# RN831X_RN861X_MCU register map
File version: v0.0.1
CPU: RN831X_RN861X_MCU r1p0, little endian, MPU, no FPU
Registers are 32-bit, read-write, reset 0x0 unless marked. A register's access mark holds for its fields unless they carry their own. Offsets are from the block's base; [hi:lo] are bit positions; {n}, {i} and the like mark numbered series; 'fields as' and 'values as' point back to an identical list.

## RTC_CORE0 — real time clock
Base 0x200B4000
Same registers: RTC_CORE1 0xA00B4000
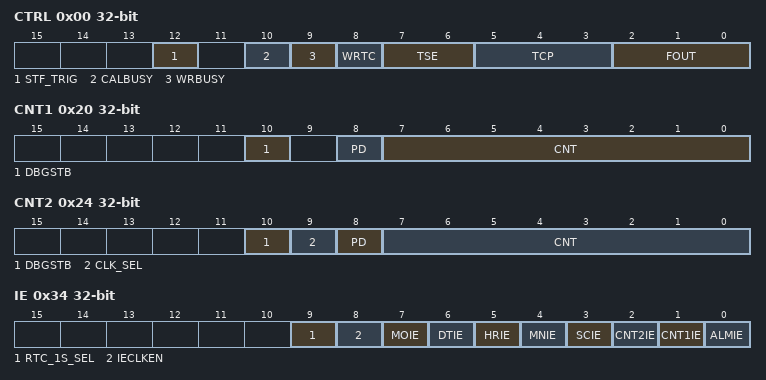
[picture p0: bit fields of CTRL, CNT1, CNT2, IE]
0x00 CTRL access per field — control register
  [12] STF_TRIG wo — software time freeze trigger bit(freezed timestamp will be save to 0x120~0x12C)
  [10] CALBUSY ro — RTC calibration busy flag
  [9] WRBUSY ro — RTC register writing busy flag (RTC register only can be changed or set when Wr_busy is 0)
  [8] WRTC rw — RTC register write enable/disable bit(controls offset 0x00-0x1C/0x3C/0xC4/0x168, except this field.)
    0=DIS (RTC register set as read_only); 1=EN (RTC register set as writable)
  [7:6] TSE rw — temparature compentation mode selection config bits.
    0=DIS (disable automatic temperature compensation); 1=AUTOEN (enable automatic cyclic temperature compensation); 2=USER0EN (enable user mode 0, automatic temperature compensation triggered by setting temperature(temperature set by user)); 3=USER1EN (enable user mode 1, automatic temperature compensation triggered by setting temperature(temperature unchangeable))
  [5:3] TCP rw — temperature compensation period bits
    0=2S (select temperature compensation period as 2 second(or 0.5s for 8025T)); 1=10S (select temperature compensation period as 10 second(or 2s for 8025T)); 2=20S (select temperature compensation period as 20 second(or 10s for 8025T)); 3=30S (select temperature compensation period as 30 second(or 30s for 8025T)); 4=1MIN (select temperature compensation period as 1 minute(not for 8025T)); 5=2MIN (select temperature compensation period as 2 minute(not for 8025T)); 6=5MIN (select temperature compensation period as 5 minute(not for 8025T)); 7=10MIN (select temperature compensation period as 10 minute(not for 8025T))
  [2:0] FOUT rw — RTC output frequency selections FOUT bits.
    0=NUL (RTCOUT forbidden); 1=PLLOUT (select RTCOUT as PLL, freq depend on PLLOUT_SEL); 2=1_30HZ (select RTCOUT as LOSC, frequency of 1/30Hz); 3=32KHZ (select RTCOUT as LOSC, frequency of 32768Hz); 4=16HZ (select RTCOUT as LOSC, frequency of 16Hz); 5=8HZ (select RTCOUT as LOSC, frequency of 8Hz); 6=4HZ (select RTCOUT as LOSC, frequency of 4Hz); 7=1HZ (select RTCOUT as LOSC, frequency of 1Hz)
0x04 SC access not given — seconds register
  [6:0] SC — seconds bits (BCD format, SC[6:4] standing for 10 seconds,SC[3:0] standing seconds)
0x08 MN access not given — minutes register
  [6:0] MN — minutes bits (BCD format, MN[6:4] standing for 10 minutes,MN[3:0] standing for minutes)
0x0C HR access not given — hours register
  [5:0] HR — hours bits (BCD format, HR[5:4] standing for 10 hours,HR[3:0] standing for hours)
0x10 DT access not given — date register
  [5:0] DT — date bits (BCD format, DT[5:4] standing for 10 date,DT[3:0] standing for date)
0x14 MO access not given — month register
  [4:0] MO — month bits (BCD format, MO[5] standing for 10 month,MO[3:0] standing for month)
0x18 YR access not given — year register
  [7:0] YR — year bits (BCD format, YR[7:4] standing for 10 year,YR[3:0] standing for year)
0x1C DW access not given — day of the week register
  [2:0] DW — day of the week bits
0x20 CNT1 access not given — RTC counter1 register
  [10] DBGSTB — RTC_CNT1 debugmode halt counting enable/disable bit
    1=PAUSE (halt counting when SoC halted by debugger); 0=COUNTINUE (keep counting when SoC halted by debugger)
  [8] PD — RTC CNT1 ON/OFF control bit
    0=ON (counter1 on (from perpetual calendar second interrupt)); 1=OFF (counter1 off, reset the counter value and restart)
  [7:0] CNT — RTC counter1 perset value bits(set CNT1 flag every (CNT+1) seconds)
0x24 CNT2 access not given — RTC counter2 register
  [10] DBGSTB — RTC_CNT2 debugmode halt counting enable/disable bit
    values as CNT1.DBGSTB
  [9] CLK_SEL — CNT2 CLK selection
    0=LOSC (select LOSC as clock source of cnt2); 1=RCL (select RCL as clock source of cnt2)
  [8] PD — RTC CNT2 ON/OFF control bit
    0=ON (counter2 on(from internal 1/256 s interrupt)); 1=OFF (counter2 off, reset the counter value)
  [7:0] CNT — RTC counter2 perset value bits(set counter2 flag every (CNT+1)/256 seconds)
0x28 SCA access not given — alarm seconds register
  [6:0] SCA — alarm seconds bits (BCD format,SCA[6:4] standing for 10 seconds,SCA[3:0] standing for seconds)
0x2C MNA access not given — alarm minitues register
  [6:0] MNA — alarm minitues bits (BCD format,MNA[6:4] standing for 10 minitues,MNA[3:0] standing for minitues)
0x30 HRA access not given — alarm hours register
  [5:0] HRA — alarm hours bits (BCD format,MNA[5:4] standing for 10 hours,MNA[3:0] standing for hours)
0x34 IE access not given — interrupt enable register
  [9] RTC_1S_SEL — RTC_1S clock source selection bit
    0=SYSCLK (select by system mode (hcmm pll_1hz, not hcmm RTC_1hz)); 1=RTC (select RTC_1hz)
  [8] IECLKEN — interrupt clock enable bit.enabled when any bit of RTC_IE[8:0] is high
    0=DIS (enable); 1=EN (disable)
  [7] MOIE — month interrupt enable bit
    0=DIS (enable); 1=EN (disable)
  [6] DTIE — date interrupt enable bit
    0=DIS (enable); 1=EN (disable)
  [5] HRIE — hour interrupt enable bit
    0=DIS (enable); 1=EN (disable)
  [4] MNIE — minute interrupt enable bit
    0=DIS (enable); 1=EN (disable)
  [3] SCIE — sencond interrupt enable bit
    0=DIS (enable); 1=EN (disable)
  [2] CNT2IE — RTC counter2 interrupt enable bit
    0=DIS (enable); 1=EN (disable)
  [1] CNT1IE — RTC counter1 interrupt enable bit
    0=DIS (enable); 1=EN (disable)
  [0] ALMIE — alarm interrupt enable bit
    0=DIS (enable); 1=EN (disable)
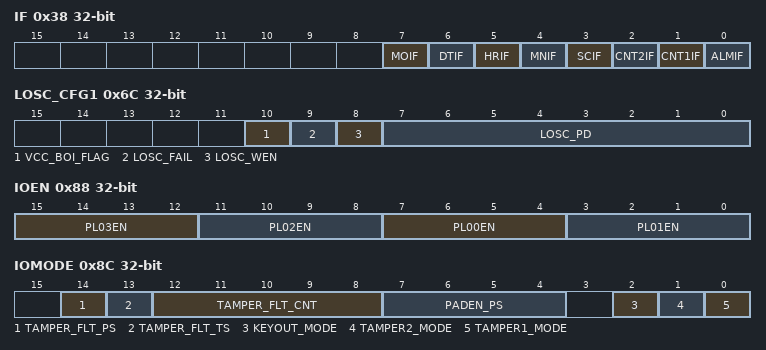
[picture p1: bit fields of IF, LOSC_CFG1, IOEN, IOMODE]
0x38 IF — RTC interrupt flags register
  [all] fields
    0=NUL (no outstanding alarm event occurred); 1=OCC (event accured)
  [7] MOIF write-1-clears — month event interrupt flag
  [6] DTIF write-1-clears — date event interrupt flag
  [5] HRIF write-1-clears — hour event interrupt flag
  [4] MNIF write-1-clears — minute event interrupt flag
  [3] SCIF write-1-clears — sencond event interrupt flag
  [2] CNT2IF write-1-clears — RTC counter2 event interrupt flag
  [1] CNT1IF write-1-clears — RTC counter1 event interrupt flag
  [0] ALMIF write-1-clears — alarm event interrupt flag
0x3C TEMP access not given — current chip temperature register No.1.The bit field range depends on RTC_MODE1 (0xEA65: [15:0], others: [9:0]), and the field access depends on RTC_CTRL_TPS (0: invalid, 1: R, 2: RW, 3: W).
  [15:0] TEMP — current chip temperature bits.[9:0]([15:0]):TEMP[9]([15]) for sign, TEMP[8:2]([15:6]) for integer part,TEMP[1:0]([5:0]) for decimal part)
0x40 PS access not given — RTC compensation curve config registers(0x44-0x60/0x130-0x148) password register
  [7:0] PS — Password bits for competition registers(44H~54H,130H~148H)
    142=ENWT (enable write of RTC competition registers); 0=DISWT (RTC competition registers write disable)
0x48 DOTA0 access not given — initial freq deviation register
  [15:0] DOTA0 — initial freq deviation bits
0x4C ALPHAL access not given — RTC low temperature coefficient ALPHA config register(Coefficient of x^2)
  [10:0] ALPHAL — RTC low temperature coefficient ALPHA config bits
0x50 ALPHAH access not given — RTC high temperature coefficient ALPHA config register(Coefficient of x^2)
  [10:0] ALPHAH — RTC high temperature coefficient ALPHA config bits
0x54 XT0 access not given — RTC temperature curve vertex temperature XT0 register
  [6:0] XT0 — RTC temperature curve vertex temperature bits
0x64 DOTAT ro — RTC compensation DOTAT register.
  [15:0] DOTAT — RTC compensation calculation result DOTAT bits
0x6C LOSC_CFG1 access not given — LOSC config register
  [10] VCC_BOI_FLAG — VCC Brown Out Indication flag
    0=NORM (VCC run normally); 1=PD (VCC power down occured)
  [9] LOSC_FAIL — LOSC running fail flag
    0=NORM (LOSC run normally); 1=FAIL (LOSC power down occured)
  [8] LOSC_WEN write-1-clears — LOSC enable bits (RTC_LOSC_CFG1_PD) write enable bit
    0=DIS (LOSC enable bits (RTC_LOSC_CFG1_PD) write disable); 1=EN (LOSC enable bits (RTC_LOSC_CFG1_PD) write enable)
  [7:0] LOSC_PD — LOSC enable/disable bits
    0=ON (enable LOSC); 168=OFF (disable LOSC)
0x74 FPTR ro — RTC PLL compensation register
  [16:0] FPTR — PLL compensation bits
0x78 FDTR1S ro — RTC compensation register(per 1 seconds)
  [5:0] FDTR1S — RTC compensation bits
0x7C FDTR30S ro — RTC compensation register(per 30 seconds)
  [6:0] FDTR30S — RTC compensation bits
0x84 FDTR120S ro — RTC compensation register(per 120 seconds)
  [8:0] FDTR120S — RTC compensation bits
0x88 IOEN access not given — IO config enable register
  [15:12] PL03EN — PL03 function configuration bits(only available when MADC_ANA_PAD_PL03_AE field =0 )
    11=KEYOUT (select as KEYOUT output pin); 0=NUL (Not function for RTC)
  [11:8] PL02EN — PL02 function configuration bits(only available when MADC_ANA_PAD_PL02_AE field =0 )
    5=IN (enable pin as TAMPER2 input or KEY0[7] input); 14=TAMPER2CLR (clean registers result of offset address 0x100~ 0x12C(TAMPER2)); 11=KEYOUT (select as KEYOUT output pin); 0=NUL (Not function for RTC)
  [7:4] PL00EN — PL00 function configuration bits(higher priority than the VCC domain)
    10=RTCOUT (enable pin as RTC_OUT); 11=KEYOUT (select as KEYOUT output pin); 0=NUL (Not function for RTC)
  [3:0] PL01EN — PL01 function configuration bits(only available when MADC_ANA_PAD_PL01_AE field =0 )
    5=IN (enable pin as TAMPER1 input or KEY0[6] input); 14=TAMPER1CLR (clean registers result of offset address 0x90-0xBC(TAMPER1)); 11=KEYOUT (select as KEYOUT output pin); 0=NUL (Not function for RTC)
0x8C IOMODE access not given — IO mode selection register
  [14] TAMPER_FLT_PS — Write enable bit for TAMPER_FLT_TS and TAMPER_FLT_CNT
  [13] TAMPER_FLT_TS — TAMPER1/TAMPER2 filter precision selection
    0=Select 2ms filter precision; 1=Select 250ms filter precision
  [12:8] TAMPER_FLT_CNT — TAMPER1/TAMPER2 filter cycles length selection
  [7:4] PADEN_PS — RTC_IOEN write enable/disable configuration
    11=WEN (RTC_IOEN write enable); 0=WDIS (RTC_IOEN write disable)
  [2] KEYOUT_MODE — KEYOUT output mode config()
    0=HIZ (Outputs low level when triggered; high-Z when released); 1=HL (Outputs low level when triggered; high level when released)
  [1] TAMPER2_MODE — TAMPER2 open cover detection mode selection
    0=EST (record the two earliest press key event); 1=LST (record the two lastest press key event)
  [0] TAMPER1_MODE — TAMPER1 open cover detection mode selection
    values as TAMPER2_MODE
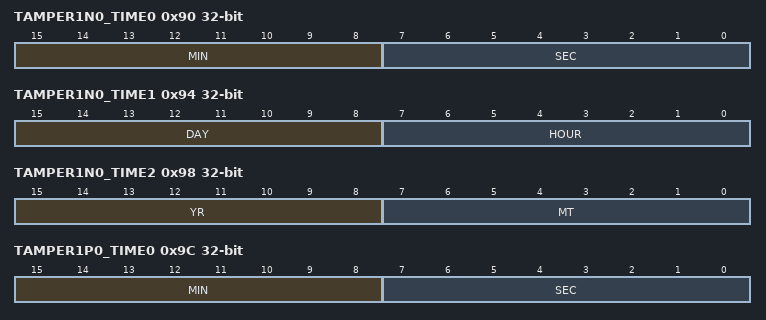
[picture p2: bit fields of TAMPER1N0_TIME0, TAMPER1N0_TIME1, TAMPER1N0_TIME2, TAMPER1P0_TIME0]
0x90 TAMPER1N0_TIME0 ro — TAMPER1 1st negedge freeze time register No.0 (seconds minute)
  [15:8] MIN — 1st negedge minute timestamp
  [7:0] SEC — 1st negedge seconds timestamp
0x94 TAMPER1N0_TIME1 ro — TAMPER1 1st negedge freeze time register No.1 (hours date)
  [15:8] DAY — 1st negedge day timestamp
  [7:0] HOUR — 1st negedge hours timestamp
0x98 TAMPER1N0_TIME2 ro — TAMPER1 1st negedge freeze time register No.2 (month year)
  [15:8] YR — 1st negedge year timestamp
  [7:0] MT — 1st negedge month timestamp
0x9C TAMPER1P0_TIME0 ro — TAMPER1 1st posedge freeze time register No.0 (seconds minute)
  [15:8] MIN — 1st posedge minute timestamp
  [7:0] SEC — 1st posedge seconds timestamp
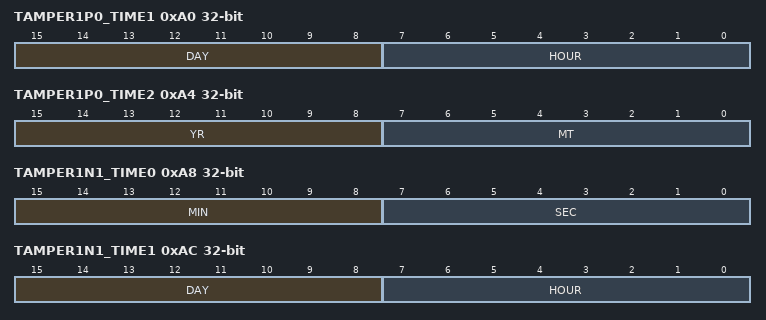
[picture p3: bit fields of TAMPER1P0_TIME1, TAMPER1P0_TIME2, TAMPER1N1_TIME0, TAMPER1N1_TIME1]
0xA0 TAMPER1P0_TIME1 ro — TAMPER1 1st posedge freeze time register No.1 (hours date)
  [15:8] DAY — 1st posedge day timestamp
  [7:0] HOUR — 1st posedge hours timestamp
0xA4 TAMPER1P0_TIME2 ro — TAMPER1 1st posedge freeze time register No.2 (month year)
  [15:8] YR — 1st posedge year timestamp
  [7:0] MT — 1st posedge month timestamp
0xA8 TAMPER1N1_TIME0 ro — TAMPER1 2st negedge freeze time register No.0 (seconds minute)
  [15:8] MIN — 2nd negedge minute timestamp
  [7:0] SEC — 2nd negedge seconds timestamp
0xAC TAMPER1N1_TIME1 ro — TAMPER1 2st negedge freeze time register No.1 (hours date)
  [15:8] DAY — 2nd negedge day timestamp
  [7:0] HOUR — 2nd negedge hours timestamp
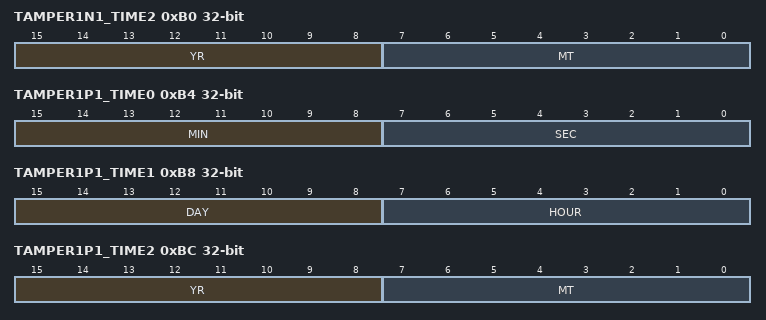
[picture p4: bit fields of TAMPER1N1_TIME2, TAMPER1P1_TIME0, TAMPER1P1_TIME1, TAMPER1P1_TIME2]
0xB0 TAMPER1N1_TIME2 ro — TAMPER1 2st negedge freeze time register No.2 (month year)
  [15:8] YR — 2nd negedge year timestamp
  [7:0] MT — 2nd negedge month timestamp
0xB4 TAMPER1P1_TIME0 ro — TAMPER1 2st posedge freeze time register No.0 (seconds minute)
  [15:8] MIN — 2nd posedge minute timestamp
  [7:0] SEC — 2nd posedge seconds timestamp
0xB8 TAMPER1P1_TIME1 ro — TAMPER1 2st posedge freeze time register No.1 (hours date)
  [15:8] DAY — 2nd posedge day timestamp
  [7:0] HOUR — 2nd posedge hours timestamp
0xBC TAMPER1P1_TIME2 ro — TAMPER1 2st posedge freeze time register No.2 (month year)
  [15:8] YR — 2nd posedge year timestamp
  [7:0] MT — 2nd posedge month timestamp
0xC4 TEMPOS access not given — auto compensation mode temperature offset register
  [5:0] TEMPOS — auto compensation mode temperature offset bits
0xC8 TPSIN access not given — RTC auto temperature compensation ADC measure value input register
  [12:0] TPSIN — RTC auto temperature compensation ADC measure value input bits
0xCC CALPS access not given — Password register for RTC calibration registers(T0-T9)
  [7:0] CALPS — Enable RTC secondary calibration registers
    168=ENABLE (enable RTC secondary calibration); 0=DISABLE (RTC secondary calibration disable)
0xD0 CAL_T0 access not given — RTC calibration register T0
  [7:0] CAL_T0 — RTC calibration register T0 bits (to calibrate RTC for 0.25ppm per bit when temprature is lower than -30 degree)
0xD4 CAL_T1 access not given — RTC calibration register T1
  [7:0] CAL_T1 — RTC calibration register T1 bits (to calibrate RTC for 0.25ppm per bit when temprature is between -30 and -20 degree)
0xD8 CAL_T2 access not given — RTC calibration register T2
  [7:0] CAL_T2 — RTC calibration register T2 bits (to calibrate RTC for 0.25ppm per bit when temprature is between -20 and -10 degree)
0xDC CAL_T3 access not given — RTC calibration register T3
  [7:0] CAL_T3 — RTC calibration register T3 bits (to calibrate RTC for 0.25ppm per bit when temprature is between -10 and 0 degree)
0xE0 CAL_T4 access not given — RTC calibration register T4
  [7:0] CAL_T4 — RTC calibration register T4 bits (to calibrate RTC for 0.25ppm per bit when temprature is between 0 and 10 degree)
{0xD0+4i} CAL_T{i} access not given (i=5..8) — RTC calibration register T{i}
  [7:0] CAL_T{i} — RTC calibration register T{i} bits (to calibrate RTC for 0.25ppm per bit when temprature is between {10i-15} and {10i-5} degree)
0xF4 CAL_T9 access not given — RTC calibration register T9
  [7:0] CAL_T9 — RTC calibration register T9 bits (to calibrate RTC for 0.25ppm per bit when temprature is higher than 75 degree)
0xF8 TEMP2 ro — current chip temperature register No.2
  [11:0] TEMP2 — current chipte mperature bits(TEMP[11] for sign, TEMP[10:4] for integer part,TEMP[3:0] for decimal part)
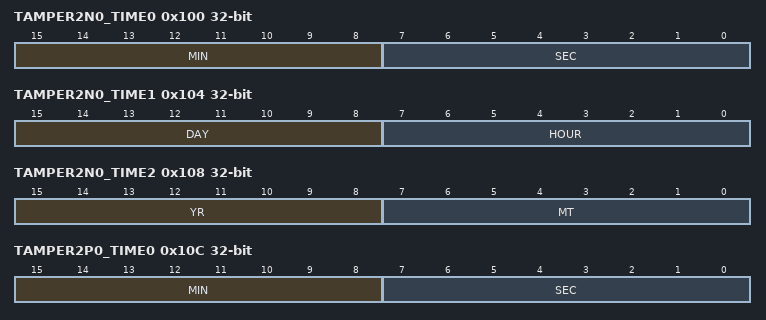
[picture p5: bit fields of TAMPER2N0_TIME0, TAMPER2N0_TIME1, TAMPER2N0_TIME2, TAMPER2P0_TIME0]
0x100 TAMPER2N0_TIME0 ro — TAMPER2 1st negedge freeze time register No.0 (seconds minute)
  fields as TAMPER1N0_TIME0
0x104 TAMPER2N0_TIME1 ro — TAMPER2 1st negedge freeze time register No.1 (hours date)
  fields as TAMPER1N0_TIME1
0x108 TAMPER2N0_TIME2 ro — TAMPER2 1st negedge freeze time register No.2 (month year)
  fields as TAMPER1N0_TIME2
0x10C TAMPER2P0_TIME0 ro — TAMPER2 1st posedge freeze time register No.0 (seconds minute)
  fields as TAMPER1P0_TIME0
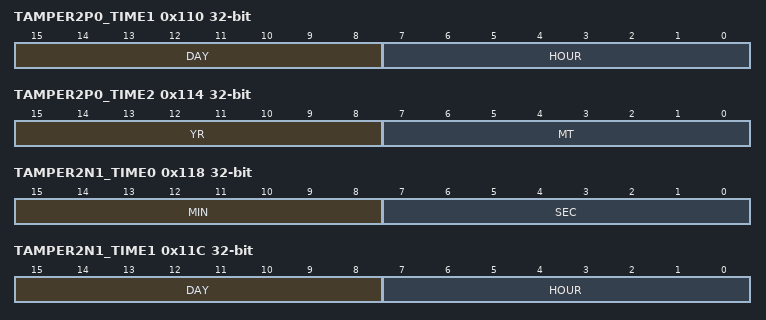
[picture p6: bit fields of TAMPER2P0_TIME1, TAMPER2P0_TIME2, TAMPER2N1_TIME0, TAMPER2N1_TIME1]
0x110 TAMPER2P0_TIME1 ro — TAMPER2 1st posedge freeze time register No.1 (hours date)
  fields as TAMPER1P0_TIME1
0x114 TAMPER2P0_TIME2 ro — TAMPER2 1st posedge freeze time register No.2 (month year)
  fields as TAMPER1P0_TIME2
0x118 TAMPER2N1_TIME0 ro — TAMPER2 2st negedge freeze time register No.0 (seconds minute)
  fields as TAMPER1N1_TIME0
0x11C TAMPER2N1_TIME1 ro — TAMPER2 2st negedge freeze time register No.1 (hours date)
  fields as TAMPER1N1_TIME1
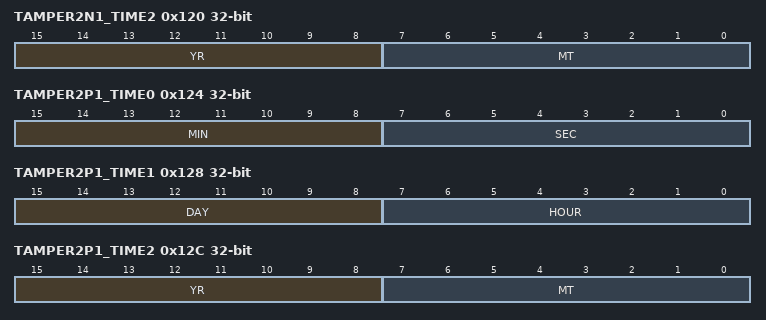
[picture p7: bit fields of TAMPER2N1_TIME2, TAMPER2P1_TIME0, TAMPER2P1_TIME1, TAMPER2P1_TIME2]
0x120 TAMPER2N1_TIME2 ro — TAMPER2 2st negedge freeze time register No.2 (month year).When TAMPER_IF[4] = 1, the software-triggered time freeze(sub-seconds)
  fields as TAMPER1N1_TIME2
0x124 TAMPER2P1_TIME0 ro — TAMPER2 2st posedge freeze time register No.0 (seconds minute). When TAMPER_IF[4] = 1, the software-triggered time freeze (seconds minute).
  [15:8] MIN — 2nd posedge(or software) freeze minute timestamp
  [7:0] SEC — 2nd posedge(or software) freeze seconds timestamp
0x128 TAMPER2P1_TIME1 ro — TAMPER2 2st posedge freeze time register No.1 (hours date). When TAMPER_IF[4] = 1, the software-triggered time freeze (hours date).
  [15:8] DAY — 2nd posedge(or software) freeze day timestamp
  [7:0] HOUR — 2nd posedge(or software) freeze hours timestamp
0x12C TAMPER2P1_TIME2 ro — TAMPER2 2st posedge freeze time register No.2 (month year). When TAMPER_IF[4] = 1, the software-triggered time freeze (month year).
  [15:8] YR — 2nd posedge(or software) freeze year timestamp
  [7:0] MT — 2nd posedge(or software) freeze month timestamp
0x130 MODE1 access not given — temperature compensation mode seletion register No.1
  [15:0] CURVE_SEL — temperature compensation mode seletion bits
0x134 XT1 access not given — RTC temperature curve vertex temperature XT1 register
  [12:0] XT1 — RTC temperature curve vertex temperature bits
0x138 ALPHA access not given — temperature coefficient ALPHA config register(Coefficient of x^1)
  [15:0] ALPHA — temperature coefficient ALPHA config bits
0x13C BETA access not given — temperature coefficient BETA config register(Coefficient of x^2)
  [14:0] BETA — temperature coefficient BETA config bits
0x140 GAMMA access not given — temperature coefficient GAMMA config register(Coefficient of x^3)
  [15:0] GAMMA — temperature coefficient GAMMA config bits
0x144 ZETA access not given — temperature coefficient ZETA config register(part1)(Coefficient of x^4 part1)
  [15:0] ZETA — temperature coefficient ZETA config bits(part1)
0x148 ZETAH access not given — temperature coefficient ZETA config register(part2)(Coefficient of x^4 part2)
  [1:0] ZETAH — temperature coefficient ZETA config bits(part2)
0x150 TPS_START wo — RTC temperature measure start register
  [0] TPS_START — RTC temperature measure start bit
0x154 TEMP_CAL ro — RTC temperature register No.3(when config as RTC_CTRL_TSE=2,the register is temperature measure result after setted RTC_TPS_START and got flag of RTC_CTRL_CAL_BUSY=0 )
  [11:0] TEMP_CAL — RTC temperature register No.3 bits
0x158 SSC ro — Sub second value register
  [15:0] SSC — Sub second value bits(1LSB=30.518us=1/32768s)
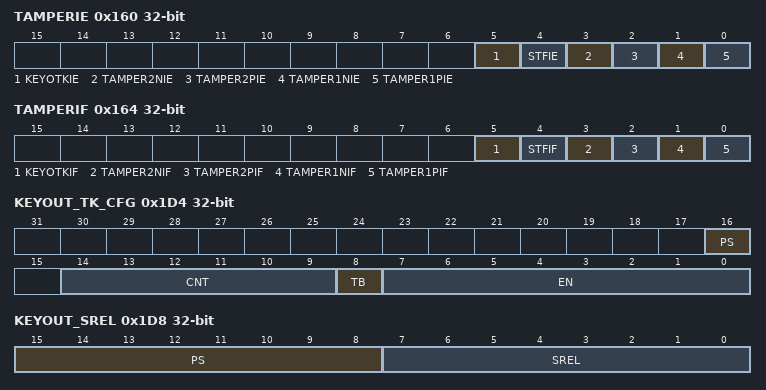
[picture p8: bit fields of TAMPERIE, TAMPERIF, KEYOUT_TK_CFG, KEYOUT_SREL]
0x160 TAMPERIE — Cover Detection Mechanism(tamper detection) interrupt enable register
  [5] KEYOTKIE — KEYOUT timed trigger interrupt enable bit
  [4] STFIE — Software time freeze interrupt enable bit
  [3] TAMPER2NIE — TAMPER2 Negative edge interrupt enable bit
  [2] TAMPER2PIE — TAMPER2 Positive edge interrupt enable bit
  [1] TAMPER1NIE — TAMPER1 Negative edge interrupt enable bit
  [0] TAMPER1PIE — TAMPER1 Positive edge interrupt enable bit
0x164 TAMPERIF access not given — Cover Detection Mechanism(tamper detection) interrupt flag register
  [5] KEYOTKIF write-1-clears — KEYOUT timed trigger interrupt flag bit(when get flag, wait >35us write to clear)
  [4] STFIF write-1-clears — Software time freeze interrupt flag bit
  [3] TAMPER2NIF write-1-clears — TAMPER2 Negative edge interrupt flag bit(when get flag, wait >35us write to clear)
  [2] TAMPER2PIF write-1-clears — TAMPER2 Positive edge interrupt flag bit(when get flag, wait >35us write to clear)
  [1] TAMPER1NIF write-1-clears — TAMPER1 Negative edge interrupt flag bit(when get flag, wait >35us write to clear)
  [0] TAMPER1PIF write-1-clears — TAMPER1 Positive edge interrupt flag bit(when get flag, wait >35us write to clear)
0x168 PLLOUT_CFG access not given — output configuration from pll clock source
  [0] FREQ_SEL — RTCOUT output signal frequency selection, when source clock was selected as PLL
    0=1HZ (config pll output as 1HZ); 1=2HZ (config pll output as 2HZ); 2=4HZ (config pll output as 4HZ); 3=8HZ (config pll output as 8HZ); 4=16HZ (config pll output as 16HZ)
0x190 BKPPS access not given — bakeup registers password(this register only reset when VBAT POR reset)
  [7:0] PS — Password bits for RTC user defines registers
    250=ENWT (enable write of RTC user defines registers); 0=DISWT (RTC user defines registers write disable)
0x194 BKP0 access not given — bakeup register No.0(this register only reset when VBAT POR reset)
  [15:0] BKP — bakeup register No.0 bits
0x198 BKP1 access not given — bakeup register No.1(this register only reset when VBAT POR reset)
  [15:0] BKP — bakeup register No.1 bits
0x19C BKP2 access not given — bakeup register No.2(this register only reset when VBAT POR reset)
  [15:0] BKP — bakeup register No.2 bits
0x1A0 BKP3 access not given — bakeup register No.3(this register only reset when VBAT POR reset)
  [15:0] BKP — bakeup register No.3 bits
0x1A4 BKP4 access not given — bakeup register No.4(this register only reset when VBAT POR reset)
  [15:0] BKP — bakeup register No.4 bits
0x1A8 BKP5 access not given — bakeup register No.5(this register only reset when VBAT POR reset)
  [15:0] BKP — bakeup register No.5 bits
0x1AC BKP6 access not given — bakeup register No.6(this register only reset when VBAT POR reset)
  [15:0] BKP — bakeup register No.6 bits
0x1B0 BKP7 access not given — bakeup register No.7(this register only reset when VBAT POR reset)
  [15:0] BKP — bakeup register No.7 bits
0x1B4 BKP8 access not given — bakeup register No.8(this register only reset when VBAT POR reset)
  [15:0] BKP — bakeup register No.8 bits
0x1B8 BKP9 access not given — bakeup register No.9(this register only reset when VBAT POR reset)
  [15:0] BKP — bakeup register No.9 bits
0x1BC BKP10 access not given — bakeup register No.10(this register only reset when VBAT POR reset)
  [15:0] BKP — bakeup register No.10 bits
0x1C0 BKP11 access not given — bakeup register No.11(this register only reset when VBAT POR reset)
  [15:0] BKP — bakeup register No.11 bits
0x1C4 BKP12 access not given — bakeup register No.12(this register only reset when VBAT POR reset)
  [15:0] BKP — bakeup register No.12 bits
0x1C8 BKP13 access not given — bakeup register No.13(this register only reset when VBAT POR reset)
  [15:0] BKP — bakeup register No.13 bits
0x1CC BKP14 access not given — bakeup register No.14(this register only reset when VBAT POR reset)
  [15:0] BKP — bakeup register No.14 bits
0x1D0 BKP15 access not given — bakeup register No.15(this register only reset when VBAT POR reset)
  [15:0] BKP — bakeup register No.15 bits
0x1D4 KEYOUT_TK_CFG — KEYOUT Periodic Trigger Configuration Register
  [16] PS — Write enable bit for other configuration bits of KEYOUT_TK_CFG
  [14:9] CNT — KEYOUT timing count target value config bits. KEYOUT timed trigger time is (CNT+1)*TS
  [8] TB — KEYOUT timing base config bit
    0=1MIN (select as 1 minute); 1=1S (select as 1 second)
  [7:0] EN — KEYOUT timed trigger enable bits
0x1D8 KEYOUT_SREL — KEYOUT Software release register
  [15:8] PS — SREL field write enable bits
    236=ENWT (enable write SREL); 0=DISWT (disable write SREL)
  [7:0] SREL — KEYOUT software release control bits
    0=RELEASE (release KEYOUT); 0=NUL (no use)
